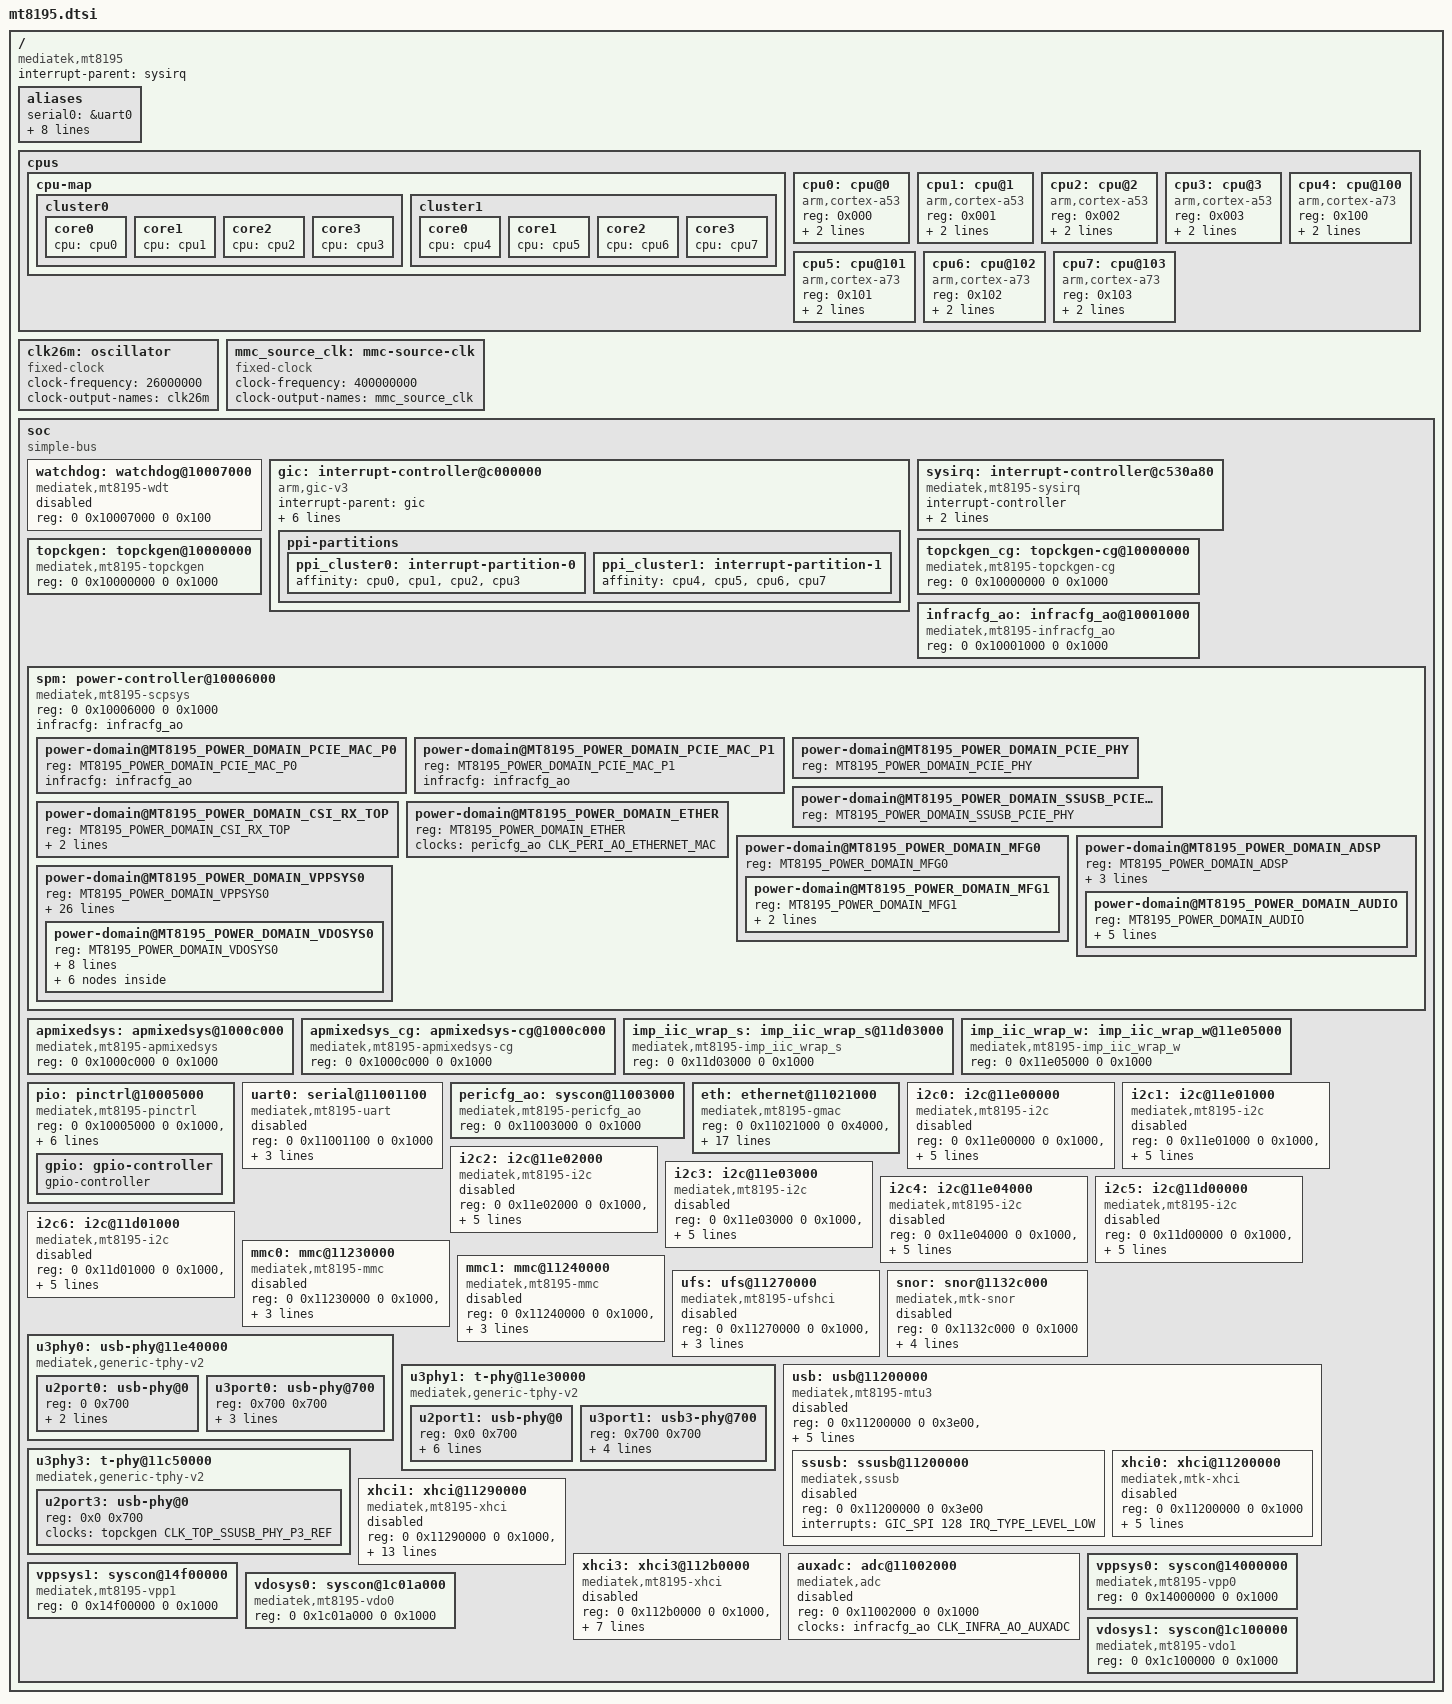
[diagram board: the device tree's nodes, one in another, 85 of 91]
// SPDX-License-Identifier: (GPL-2.0 OR MIT)
/*
 * Copyright (C) 2021 MediaTek Inc.
 * Copyright (C) 2021 BayLibre, SAS
 * Author: Ben Ho <ben.ho@mediatek.com>
 *         Erin Lo <erin.lo@mediatek.com>
 *         Fabien Parent <fparent@baylibre.com>
 */

#include <dt-bindings/gpio/gpio.h>
#include <dt-bindings/clock/mt8195-clk.h>
#include <dt-bindings/interrupt-controller/irq.h>
#include <dt-bindings/interrupt-controller/arm-gic.h>
#include <dt-bindings/pinctrl/mediatek,mt8195-pinfunc.h>
#include <dt-bindings/power/mt8195-power.h>
#include <dt-bindings/phy/phy.h>

/ {
	compatible = "mediatek,mt8195";
	interrupt-parent = <&sysirq>;
	#address-cells = <2>;
	#size-cells = <2>;

	aliases {
		serial0 = &uart0;
		ethernet0 = &eth;
		i2c0 = &i2c0;
		i2c1 = &i2c1;
		i2c2 = &i2c2;
		i2c3 = &i2c3;
		i2c4 = &i2c4;
		i2c5 = &i2c5;
		i2c6 = &i2c6;
	};

	cpus {
		#address-cells = <1>;
		#size-cells = <0>;

		cpu-map {
			cluster0 {
				core0 {
					cpu = <&cpu0>;
				};
				core1 {
					cpu = <&cpu1>;
				};
				core2 {
					cpu = <&cpu2>;
				};
				core3 {
					cpu = <&cpu3>;
				};
			};

			cluster1 {
				core0 {
					cpu = <&cpu4>;
				};
				core1 {
					cpu = <&cpu5>;
				};
				core2 {
					cpu = <&cpu6>;
				};
				core3 {
					cpu = <&cpu7>;
				};
			};
		};

		cpu0: cpu@0 {
			device_type = "cpu";
			compatible = "arm,cortex-a53";
			reg = <0x000>;
			enable-method = "psci";
			capacity-dmips-mhz = <741>;
		};

		cpu1: cpu@1 {
			device_type = "cpu";
			compatible = "arm,cortex-a53";
			reg = <0x001>;
			enable-method = "psci";
			capacity-dmips-mhz = <741>;
		};

		cpu2: cpu@2 {
			device_type = "cpu";
			compatible = "arm,cortex-a53";
			reg = <0x002>;
			enable-method = "psci";
			capacity-dmips-mhz = <741>;
		};

		cpu3: cpu@3 {
			device_type = "cpu";
			compatible = "arm,cortex-a53";
			reg = <0x003>;
			enable-method = "psci";
			capacity-dmips-mhz = <741>;
		};

		cpu4: cpu@100 {
			device_type = "cpu";
			compatible = "arm,cortex-a73";
			reg = <0x100>;
			enable-method = "psci";
			capacity-dmips-mhz = <1024>;
		};

		cpu5: cpu@101 {
			device_type = "cpu";
			compatible = "arm,cortex-a73";
			reg = <0x101>;
			enable-method = "psci";
			capacity-dmips-mhz = <1024>;
		};

		cpu6: cpu@102 {
			device_type = "cpu";
			compatible = "arm,cortex-a73";
			reg = <0x102>;
			enable-method = "psci";
			capacity-dmips-mhz = <1024>;
		};

		cpu7: cpu@103 {
			device_type = "cpu";
			compatible = "arm,cortex-a73";
			reg = <0x103>;
			enable-method = "psci";
			capacity-dmips-mhz = <1024>;
		};
	};

	clk26m: oscillator {
		compatible = "fixed-clock";
		#clock-cells = <0>;
		clock-frequency = <26000000>;
		clock-output-names = "clk26m";
	};

	mmc_source_clk: mmc-source-clk{
		compatible = "fixed-clock";
		#clock-cells = <0>;
		clock-frequency = <400000000>;
		clock-output-names = "mmc_source_clk";
	};

	soc {
		#address-cells = <2>;
		#size-cells = <2>;
		compatible = "simple-bus";
		ranges;

		watchdog: watchdog@10007000 {
			compatible = "mediatek,mt8195-wdt",
				      "mediatek,wdt";
			reg = <0 0x10007000 0 0x100>;
			status = "disabled";
		};

		gic: interrupt-controller@c000000 {
			compatible = "arm,gic-v3";
			#interrupt-cells = <4>;
			interrupt-parent = <&gic>;
			interrupt-controller;
			reg = <0 0x0c000000 0 0x40000>,  /* GICD */
			      <0 0x0c100000 0 0x200000>, /* GICR */
			      <0 0x0c400000 0 0x2000>,   /* GICC */
			      <0 0x0c410000 0 0x1000>,   /* GICH */
			      <0 0x0c420000 0 0x2000>;   /* GICV */

			interrupts = <GIC_PPI 9 IRQ_TYPE_LEVEL_HIGH 0>;
			ppi-partitions {
				ppi_cluster0: interrupt-partition-0 {
					affinity = <&cpu0 &cpu1 &cpu2 &cpu3>;
				};
				ppi_cluster1: interrupt-partition-1 {
					affinity = <&cpu4 &cpu5 &cpu6 &cpu7>;
				};
			};
		};

		sysirq: interrupt-controller@c530a80 {
			compatible = "mediatek,mt8195-sysirq",
				     "mediatek,mt6577-sysirq";
			interrupt-controller;
			#interrupt-cells = <3>;
			interrupt-parent = <&gic>;
			reg = <0 0x0c530a80 0 0x50>;
		};

		topckgen: topckgen@10000000 {
			compatible = "mediatek,mt8195-topckgen";
			reg = <0 0x10000000 0 0x1000>;
			#clock-cells = <1>;
		};

		topckgen_cg: topckgen-cg@10000000 {
			compatible = "mediatek,mt8195-topckgen-cg";
			reg = <0 0x10000000 0 0x1000>;
			#clock-cells = <1>;
		};

		infracfg_ao: infracfg_ao@10001000 {
			compatible = "mediatek,mt8195-infracfg_ao", "syscon";
			reg = <0 0x10001000 0 0x1000>;
			#clock-cells = <1>;
		};

		spm: power-controller@10006000 {
			compatible = "mediatek,mt8195-scpsys";
			reg = <0 0x10006000 0 0x1000>;
			#address-cells = <1>;
			#size-cells = <0>;
			#power-domain-cells = <1>;
			infracfg = <&infracfg_ao>;

			power-domain@MT8195_POWER_DOMAIN_PCIE_MAC_P0 {
				reg = <MT8195_POWER_DOMAIN_PCIE_MAC_P0>;
				infracfg = <&infracfg_ao>;
				#power-domain-cells = <0>;
			};

			power-domain@MT8195_POWER_DOMAIN_PCIE_MAC_P1 {
				reg = <MT8195_POWER_DOMAIN_PCIE_MAC_P1>;
				infracfg = <&infracfg_ao>;
				#power-domain-cells = <0>;
			};

			power-domain@MT8195_POWER_DOMAIN_PCIE_PHY {
				reg = <MT8195_POWER_DOMAIN_PCIE_PHY>;
				#power-domain-cells = <0>;
			};

			power-domain@MT8195_POWER_DOMAIN_SSUSB_PCIE_PHY {
				reg = <MT8195_POWER_DOMAIN_SSUSB_PCIE_PHY>;
				#power-domain-cells = <0>;
			};

			power-domain@MT8195_POWER_DOMAIN_CSI_RX_TOP {
				reg = <MT8195_POWER_DOMAIN_CSI_RX_TOP>;
				clocks = <&topckgen CLK_TOP_SENINF>,
					 <&topckgen CLK_TOP_SENINF2>;
				clock-names = "csi_rx_top", "csi_rx_top1";
				#power-domain-cells = <0>;
			};

			power-domain@MT8195_POWER_DOMAIN_ETHER {
				reg = <MT8195_POWER_DOMAIN_ETHER>;
				clocks = <&pericfg_ao CLK_PERI_AO_ETHERNET_MAC>;
				clock-names = "ether";
				#power-domain-cells = <0>;
			};

			power-domain@MT8195_POWER_DOMAIN_MFG0 {
				reg = <MT8195_POWER_DOMAIN_MFG0>;
				#address-cells = <1>;
				#size-cells = <0>;
				#power-domain-cells = <1>;

				power-domain@MT8195_POWER_DOMAIN_MFG1 {
					reg = <MT8195_POWER_DOMAIN_MFG1>;
					clocks = <&apmixedsys CLK_APMIXED_MFGPLL>;
					clock-names = "mfg";
					infracfg = <&infracfg_ao>;
					#address-cells = <1>;
					#size-cells = <0>;
					#power-domain-cells = <1>;
				};
			};

			power-domain@MT8195_POWER_DOMAIN_ADSP {
				reg = <MT8195_POWER_DOMAIN_ADSP>;
				clocks = <&topckgen CLK_TOP_ADSP>,
					 <&topckgen CLK_TOP_AUDIO_LOCAL_BUS>;
				clock-names = "adsp", "adsp1";
				#address-cells = <1>;
				#size-cells = <0>;
				infracfg = <&infracfg_ao>;
				#power-domain-cells = <1>;

				power-domain@MT8195_POWER_DOMAIN_AUDIO {
					reg = <MT8195_POWER_DOMAIN_AUDIO>;
					clocks = <&topckgen CLK_TOP_A1SYS_HP>,
						 <&topckgen CLK_TOP_AUD_INTBUS>,
						 <&topckgen CLK_TOP_AUDIO_LOCAL_BUS>,
						 <&infracfg_ao CLK_INFRA_AO_AUDIO_26M_B>;
					clock-names = "audio", "audio1", "audio-2",
							"audio-3";
					infracfg = <&infracfg_ao>;
					#power-domain-cells = <0>;
				};
			};

			power-domain@MT8195_POWER_DOMAIN_VPPSYS0 {
				reg = <MT8195_POWER_DOMAIN_VPPSYS0>;
				clocks = <&topckgen CLK_TOP_VPP>,
					 <&topckgen CLK_TOP_CAM>,
					 <&topckgen CLK_TOP_CCU>,
					 <&topckgen CLK_TOP_IMG>,
					 <&topckgen CLK_TOP_VENC>,
					 <&topckgen CLK_TOP_VDEC>,
					 <&topckgen CLK_TOP_WPE_VPP>,
					 <&topckgen CLK_TOP_CFG_VPP0>,
					 <&vppsys0 CLK_VPP0_SMI_COMMON>,
					 <&vppsys0 CLK_VPP0_GALS_VDO0_LARB0>,
					 <&vppsys0 CLK_VPP0_GALS_VDO0_LARB1>,
					 <&vppsys0 CLK_VPP0_GALS_VENCSYS>,
					 <&vppsys0 CLK_VPP0_GALS_VENCSYS_CORE1>,
					 <&vppsys0 CLK_VPP0_GALS_INFRA>,
					 <&vppsys0 CLK_VPP0_GALS_CAMSYS>,
					 <&vppsys0 CLK_VPP0_GALS_VPP1_LARB5>,
					 <&vppsys0 CLK_VPP0_GALS_VPP1_LARB6>,
					 <&vppsys0 CLK_VPP0_SMI_REORDER>,
					 <&vppsys0 CLK_VPP0_SMI_IOMMU>,
					 <&vppsys0 CLK_VPP0_GALS_IMGSYS_CAMSYS>,
					 <&vppsys0 CLK_VPP0_GALS_EMI0_EMI1>,
					 <&vppsys0 CLK_VPP0_SMI_SUB_COMMON_REORDER>,
					 <&vppsys0 CLK_VPP0_SMI_RSI>,
					 <&vppsys0 CLK_VPP0_SMI_COMMON_LARB4>,
					 <&vppsys0 CLK_VPP0_GALS_VDEC_VDEC_CORE1>,
					 <&vppsys0 CLK_VPP0_GALS_VPP1_WPE>,
					 <&vppsys0 CLK_VPP0_GALS_VDO0_VDO1_VENCSYS_CORE1>;
				clock-names = "vppsys", "vppsys1", "vppsys2", "vppsys3",
					      "vppsys4", "vppsys5", "vppsys6", "vppsys7",
					      "vppsys0-0", "vppsys0-1", "vppsys0-2", "vppsys0-3",
					      "vppsys0-4", "vppsys0-5", "vppsys0-6", "vppsys0-7",
					      "vppsys0-8", "vppsys0-9", "vppsys0-10", "vppsys0-11",
					      "vppsys0-12", "vppsys0-13", "vppsys0-14",
					      "vppsys0-15", "vppsys0-16", "vppsys0-17",
					      "vppsys0-18";
				infracfg = <&infracfg_ao>;
				#address-cells = <1>;
				#size-cells = <0>;
				#power-domain-cells = <1>;

				power-domain@MT8195_POWER_DOMAIN_VDOSYS0 {
					reg = <MT8195_POWER_DOMAIN_VDOSYS0>;
					clocks = <&topckgen CLK_TOP_CFG_VDO0>,
						 <&vdosys0 CLK_VDO0_SMI_GALS>,
						 <&vdosys0 CLK_VDO0_SMI_COMMON>,
						 <&vdosys0 CLK_VDO0_SMI_EMI>,
						 <&vdosys0 CLK_VDO0_SMI_IOMMU>,
						 <&vdosys0 CLK_VDO0_SMI_LARB>,
						 <&vdosys0 CLK_VDO0_SMI_RSI>;
					clock-names = "vdosys0", "vdosys0-0", "vdosys0-1",
						      "vdosys0-2", "vdosys0-3",
						      "vdosys0-4", "vdosys0-5";
					infracfg = <&infracfg_ao>;
					#address-cells = <1>;
					#size-cells = <0>;
					#power-domain-cells = <1>;

					power-domain@MT8195_POWER_DOMAIN_VPPSYS1 {
						reg = <MT8195_POWER_DOMAIN_VPPSYS1>;
						clocks = <&topckgen CLK_TOP_CFG_VPP1>,
							 <&vppsys1 CLK_VPP1_VPPSYS1_GALS>,
							 <&vppsys1 CLK_VPP1_VPPSYS1_LARB>;
						clock-names = "vppsys1", "vppsys1-0",
							      "vppsys1-1";
						infracfg = <&infracfg_ao>;
						#power-domain-cells = <0>;
					};

					power-domain@MT8195_POWER_DOMAIN_VDOSYS1 {
						reg = <MT8195_POWER_DOMAIN_VDOSYS1>;
						clocks = <&topckgen CLK_TOP_CFG_VDO1>,
							 <&vdosys1 CLK_VDO1_SMI_LARB2>,
							 <&vdosys1 CLK_VDO1_SMI_LARB3>,
							 <&vdosys1 CLK_VDO1_GALS>;
						clock-names = "vdosys1", "vdosys1-0",
							      "vdosys1-1", "vdosys1-2";
						infracfg = <&infracfg_ao>;
						#address-cells = <1>;
						#size-cells = <0>;
						#power-domain-cells = <1>;

						power-domain@MT8195_POWER_DOMAIN_DP_TX {
							reg = <MT8195_POWER_DOMAIN_DP_TX>;
							infracfg = <&infracfg_ao>;
							#power-domain-cells = <0>;
						};

						power-domain@MT8195_POWER_DOMAIN_EPD_TX {
							reg = <MT8195_POWER_DOMAIN_EPD_TX>;
							infracfg = <&infracfg_ao>;
							#power-domain-cells = <0>;
						};

						power-domain@MT8195_POWER_DOMAIN_HDMI_TX {
							reg = <MT8195_POWER_DOMAIN_HDMI_TX>;
							clocks = <&topckgen CLK_TOP_HDMI_APB>;
							clock-names = "hdmi_tx";
							#power-domain-cells = <0>;
						};

						power-domain@MT8195_POWER_DOMAIN_HDMI_RX {
							reg = <MT8195_POWER_DOMAIN_HDMI_RX>;
							clocks = <&topckgen CLK_TOP_HDMI_APB>;
							clock-names = "hdmi_rx";
							#power-domain-cells = <0>;
						};
					};
				};
			};
		};

		apmixedsys: apmixedsys@1000c000 {
			compatible = "mediatek,mt8195-apmixedsys";
			reg = <0 0x1000c000 0 0x1000>;
			#clock-cells = <1>;
		};

		apmixedsys_cg: apmixedsys-cg@1000c000 {
			compatible = "mediatek,mt8195-apmixedsys-cg";
			reg = <0 0x1000c000 0 0x1000>;
			#clock-cells = <1>;
		};

		imp_iic_wrap_s: imp_iic_wrap_s@11d03000 {
			compatible = "mediatek,mt8195-imp_iic_wrap_s";
			reg = <0 0x11d03000 0 0x1000>;
			#clock-cells = <1>;
		};

		imp_iic_wrap_w: imp_iic_wrap_w@11e05000 {
			compatible = "mediatek,mt8195-imp_iic_wrap_w";
			reg = <0 0x11e05000 0 0x1000>;
			#clock-cells = <1>;
		};

		pio: pinctrl@10005000 {
			compatible = "mediatek,mt8195-pinctrl";
			reg = <0 0x10005000 0 0x1000>,
			      <0 0x11d10000 0 0x1000>,
			      <0 0x11d30000 0 0x1000>,
			      <0 0x11d40000 0 0x1000>,
			      <0 0x11e20000 0 0x1000>,
			      <0 0x11eb0000 0 0x1000>,
			      <0 0x11f40000 0 0x1000>,
			      <0 0x1000b000 0 0x1000>;
			reg-names = "iocfg0", "iocfg_bm", "iocfg_bl",
				    "iocfg_br", "iocfg_lm", "iocfg_rb",
				    "iocfg_tl", "eint";
			gpio: gpio-controller {
				gpio-controller;
				#gpio-cells = <2>;
			};
		};

		uart0: serial@11001100 {
			compatible = "mediatek,mt8195-uart",
				     "mediatek,hsuart";
			reg = <0 0x11001100 0 0x1000>;
			interrupts = <GIC_SPI 91 IRQ_TYPE_LEVEL_LOW>;
			clock-frequency = <26000000>;
			clocks = <&clk26m>, <&clk26m>;
			clock-names = "baud", "bus";
			status = "disabled";
		};

		pericfg_ao: syscon@11003000 {
			compatible = "mediatek,mt8195-pericfg_ao", "syscon";
			reg = <0 0x11003000 0 0x1000>;
			#clock-cells = <1>;
		};

		eth: ethernet@11021000 {
			compatible = "mediatek,mt8195-gmac", "snps,dwmac-5.10a";
			reg = <0 0x11021000 0 0x4000>,
			/* TODO: remove it when power driver is ready*/
				  <0 0x10006000 0 0x1000>;
			interrupts = <GIC_SPI 716 IRQ_TYPE_LEVEL_HIGH 0>;
			interrupt-names = "macirq";
			clock-names = "axi",
				      "apb",
				      "mac_cg",
				      "mac_main",
				      "ptp_ref",
				      "rmii_internal";
			clocks = <&pericfg_ao CLK_PERI_AO_ETHERNET>,
				 <&pericfg_ao CLK_PERI_AO_ETHERNET_BUS>,
				 <&pericfg_ao CLK_PERI_AO_ETHERNET_MAC>,
				 <&topckgen CLK_TOP_SNPS_ETH_250M>,
				 <&topckgen CLK_TOP_SNPS_ETH_62P4M_PTP>,
				 <&topckgen CLK_TOP_SNPS_ETH_50M_RMII>;
			assigned-clocks = <&topckgen CLK_TOP_SNPS_ETH_250M>,
					  <&topckgen CLK_TOP_SNPS_ETH_62P4M_PTP>,
					  <&topckgen CLK_TOP_SNPS_ETH_50M_RMII>;
			assigned-clock-parents = <&topckgen CLK_TOP_ETHPLL_D2>,
						 <&topckgen CLK_TOP_ETHPLL_D8>,
						 <&topckgen CLK_TOP_ETHPLL_D10>;
			/*power-domains = <&spm MT8195_POWER_DOMAIN_ETHER>;*/
			mediatek,pericfg = <&infracfg_ao>;
			status = "okay";
		};

		i2c0: i2c@11e00000 {
			compatible = "mediatek,mt8195-i2c";
			reg = <0 0x11e00000 0 0x1000>,
			      <0 0x10220080 0 0x80>;
			clock-div = <1>;
			clocks = <&imp_iic_wrap_w CLK_IMP_IIC_WRAP_W_I2C0>,
				 <&infracfg_ao CLK_INFRA_AO_APDMA_B>;
			clock-names = "main", "dma";
			#address-cells = <1>;
			#size-cells = <0>;
			status = "disabled";
		};

		i2c1: i2c@11e01000 {
			compatible = "mediatek,mt8195-i2c";
			reg = <0 0x11e01000 0 0x1000>,
			      <0 0x10220200 0 0x80>;
			clock-div = <1>;
			clocks = <&imp_iic_wrap_w CLK_IMP_IIC_WRAP_W_I2C1>,
				 <&infracfg_ao CLK_INFRA_AO_APDMA_B>;
			clock-names = "main", "dma";
			#address-cells = <1>;
			#size-cells = <0>;
			status = "disabled";
		};

		i2c2: i2c@11e02000 {
			compatible = "mediatek,mt8195-i2c";
			reg = <0 0x11e02000 0 0x1000>,
			      <0 0x10220380 0 0x80>;
			clock-div = <1>;
			clocks = <&imp_iic_wrap_w CLK_IMP_IIC_WRAP_W_I2C2>,
				 <&infracfg_ao CLK_INFRA_AO_APDMA_B>;
			clock-names = "main", "dma";
			#address-cells = <1>;
			#size-cells = <0>;
			status = "disabled";
		};

		i2c3: i2c@11e03000 {
			compatible = "mediatek,mt8195-i2c";
			reg = <0 0x11e03000 0 0x1000>,
			      <0 0x10220480 0 0x80>;
			clock-div = <1>;
			clocks = <&imp_iic_wrap_w CLK_IMP_IIC_WRAP_W_I2C3>,
				 <&infracfg_ao CLK_INFRA_AO_APDMA_B>;
			clock-names = "main", "dma";
			#address-cells = <1>;
			#size-cells = <0>;
			status = "disabled";
		};

		i2c4: i2c@11e04000 {
			compatible = "mediatek,mt8195-i2c";
			reg = <0 0x11e04000 0 0x1000>,
			      <0 0x10220500 0 0x80>;
			clock-div = <1>;
			clocks = <&imp_iic_wrap_w CLK_IMP_IIC_WRAP_W_I2C4>,
				 <&infracfg_ao CLK_INFRA_AO_APDMA_B>;
			clock-names = "main", "dma";
			#address-cells = <1>;
			#size-cells = <0>;
			status = "disabled";
		};

		i2c5: i2c@11d00000 {
			compatible = "mediatek,mt8195-i2c";
			reg = <0 0x11d00000 0 0x1000>,
			      <0 0x10220580 0 0x80>;
			clock-div = <1>;
			clocks = <&imp_iic_wrap_s CLK_IMP_IIC_WRAP_S_I2C5>,
				 <&infracfg_ao CLK_INFRA_AO_APDMA_B>;
			clock-names = "main", "dma";
			#address-cells = <1>;
			#size-cells = <0>;
			status = "disabled";
		};

		i2c6: i2c@11d01000 {
			compatible = "mediatek,mt8195-i2c";
			reg = <0 0x11d01000 0 0x1000>,
				<0 0x10220600 0 0x80>;
			clock-div = <1>;
			clocks = <&imp_iic_wrap_s CLK_IMP_IIC_WRAP_S_I2C6>,
				<&infracfg_ao CLK_INFRA_AO_APDMA_B>;
			clock-names = "main", "dma";
			#address-cells = <1>;
			#size-cells = <0>;
			status = "disabled";
		};

		mmc0: mmc@11230000 {
			compatible = "mediatek,mt8195-mmc",
				     "mediatek,mt8183-mmc";
			reg = <0 0x11230000 0 0x1000>,
			      <0 0x11f50000 0 0x1000>;
			interrupts = <GIC_SPI 77 IRQ_TYPE_LEVEL_LOW>;
			clocks = <&mmc_source_clk>,
				 <&clk26m>,
				 <&clk26m>;
			clock-names = "source", "hclk", "source_cg";
			status = "disabled";
		};

		mmc1: mmc@11240000 {
			compatible = "mediatek,mt8195-mmc",
				     "mediatek,mt8183-mmc";
			reg = <0 0x11240000 0 0x1000>,
			      <0 0x11c70000 0 0x1000>;
			interrupts = <GIC_SPI 135 IRQ_TYPE_LEVEL_LOW>;
			clocks = <&mmc_source_clk>,
				 <&clk26m>,
				 <&clk26m>;
			clock-names = "source", "hclk", "source_cg";
			status = "disabled";
		};

		ufs: ufs@11270000 {
			compatible = "mediatek,mt8195-ufshci",
				     "mediatek,mt8183-ufshci";
			reg = <0 0x11270000 0 0x1000>,
			      <0 0x11f50000 0 0x1000>;
			interrupts = <GIC_SPI 77 IRQ_TYPE_LEVEL_LOW>;
			clocks = <&mmc_source_clk>,
				 <&clk26m>,
				 <&clk26m>;
			clock-names = "source", "hclk", "source_cg";
			status = "disabled";
		};

		snor: snor@1132c000 {
			compatible = "mediatek,mtk-snor";
			reg = <0 0x1132c000 0 0x1000>;
			interrupts = <GIC_SPI 825 IRQ_TYPE_LEVEL_HIGH 0>;
			clocks = <&topckgen CLK_TOP_SPINOR>,
				 <&pericfg_ao CLK_PERI_AO_FLASHIF_FLASH>,
				 <&pericfg_ao CLK_PERI_AO_FLASHIF_BUS>;
			clock-names = "spi", "sf", "axi";
			#address-cells = <1>;
			#size-cells = <0>;
			status = "disabled";
		};

		u3phy0: usb-phy@11e40000 {
			compatible = "mediatek,generic-tphy-v2";
			#address-cells = <1>;
			#size-cells = <1>;
			ranges = <0 0 0x11e40000 0xe00>;
			status = "okay";

			u2port0: usb-phy@0 {
				reg = <0 0x700>;
				clocks = <&topckgen CLK_TOP_SSUSB_PHY_REF>,
					 <&apmixedsys CLK_APMIXED_USB1PLL>;
				clock-names = "ref", "da_ref";
				#phy-cells = <1>;
				status = "okay";
			};

			u3port0: usb-phy@700 {
				reg = <0x700 0x700>;
				clocks = <&apmixedsys_cg CLK_APMIXED_PLL_SSUSB26M>,
					 <&topckgen CLK_TOP_SSUSB_PHY_REF>;
				clock-names = "ref", "da_ref";
				#phy-cells = <1>;
				status = "okay";
			};
		};

		u3phy1: t-phy@11e30000 {
			compatible = "mediatek,generic-tphy-v2";
			#address-cells = <1>;
			#size-cells = <1>;
			ranges = <0 0 0x11e30000 0xe00>;
			status = "okay";

			u2port1: usb-phy@0 {
				reg = <0x0 0x700>;
				clocks = <&topckgen CLK_TOP_SSUSB_PHY_P1_REF>,
					 <&apmixedsys CLK_APMIXED_USB1PLL>;
				clock-names = "ref", "da_ref";
				#phy-cells = <1>;
				mediatek,eye-vrt = <4>;
				mediatek,eye-term = <4>;
				mediatek,discth = <4>;
				mediatek,pre-emphasis = <0>;
				status = "okay";
			};

			u3port1: usb3-phy@700 {
				reg = <0x700 0x700>;
				clocks = <&apmixedsys_cg CLK_APMIXED_PLL_SSUSB26M>,
					<&topckgen CLK_TOP_SSUSB_PHY_P1_REF>;
				clock-names = "ref", "da_ref";
				#phy-cells = <1>;
				mediatek,force-mode;
				status = "okay";
			};
		};

		usb: usb@11200000 {
			compatible ="mediatek,mt8195-mtu3", "mediatek,mtu3";
			reg = <0 0x11200000 0 0x3e00>,
			      <0 0x11203e00 0 0x0100>;
			reg-names = "mac", "ippc";
			phys = <&u2port0 PHY_TYPE_USB2>;
			clocks = <&infracfg_ao CLK_INFRA_AO_SSUSB>,
				 <&topckgen CLK_TOP_SSUSB_REF>,
				 <&infracfg_ao CLK_INFRA_AO_SSUSB_XHCI>;
			clock-names = "sys_ck", "ref_ck", "mcu_ck";
			#address-cells = <2>;
			#size-cells = <2>;
			ranges;
			status = "disabled";

			ssusb: ssusb@11200000 {
				compatible = "mediatek,ssusb";
				reg = <0 0x11200000 0 0x3e00>;
				reg-names = "mac";
				interrupts = <GIC_SPI 128 IRQ_TYPE_LEVEL_LOW>;
				status = "disabled";
			};

			xhci0: xhci@11200000 {
				compatible = "mediatek,mtk-xhci";
				reg = <0 0x11200000 0 0x1000>;
				reg-names = "mac";
				interrupts = <GIC_SPI 129 IRQ_TYPE_LEVEL_LOW>;
				clocks = <&infracfg_ao CLK_INFRA_AO_SSUSB>,
					 <&infracfg_ao CLK_INFRA_AO_SSUSB_XHCI>,
					 <&topckgen CLK_TOP_SSUSB_REF>,
					 <&apmixedsys CLK_APMIXED_USB1PLL>;
				clock-names = "sys_ck", "xhci_ck", "ref_ck", "mcu_ck";
				status = "disabled";
			};
		};

		u3phy3: t-phy@11c50000 {
			compatible = "mediatek,generic-tphy-v2";
			#address-cells = <1>;
			#size-cells = <1>;
			ranges = <0 0 0x11c50000 0x700>;
			status = "okay";

			u2port3: usb-phy@0 {
				reg = <0x0 0x700>;
				clocks = <&topckgen CLK_TOP_SSUSB_PHY_P3_REF>;
				clock-names = "ref";
				#phy-cells = <1>;
			};
		};

		xhci1: xhci@11290000 {
			compatible = "mediatek,mt8195-xhci",
				     "mediatek,mtk-xhci";
			reg = <0 0x11290000 0 0x1000>,
			      <0 0x11293e00 0 0x0100>;
			reg-names = "mac", "ippc";
			interrupts = <GIC_SPI 530 IRQ_TYPE_LEVEL_HIGH 0>;
			phys = <&u2port1 PHY_TYPE_USB2>,
			       <&u3port1 PHY_TYPE_USB3>;
			assigned-clocks = <&topckgen CLK_TOP_USB_TOP_1P>,
					  <&topckgen CLK_TOP_SSUSB_XHCI_1P>;
			assigned-clock-parents = <&topckgen CLK_TOP_UNIVPLL_D5_D4>,
						 <&topckgen CLK_TOP_UNIVPLL_D5_D4>;
			clocks = <&pericfg_ao CLK_PERI_AO_SSUSB_1P_BUS>,
				 <&pericfg_ao CLK_PERI_AO_SSUSB_1P_XHCI>,
				 <&topckgen CLK_TOP_SSUSB_P1_REF>,
				 <&apmixedsys CLK_APMIXED_USB1PLL>;
			clock-names = "sys_ck", "xhci_ck", "ref_ck", "mcu_ck";
			status = "disable";
		};

		xhci3: xhci3@112b0000 {
			compatible = "mediatek,mt8195-xhci",
				     "mediatek,mtk-xhci";
			reg = <0 0x112b0000 0 0x1000>,
			      <0 0x112b3e00 0 0x0100>;
			reg-names = "mac", "ippc";
			interrupts = <GIC_SPI 536 IRQ_TYPE_LEVEL_HIGH>;
			phys = <&u2port3 PHY_TYPE_USB2>;
			clocks = <&pericfg_ao CLK_PERI_AO_SSUSB_3P_BUS>,
				 <&pericfg_ao CLK_PERI_AO_SSUSB_3P_XHCI>,
				 <&topckgen CLK_TOP_SSUSB_P3_REF>;
			clock-names = "sys_ck", "xhci_ck", "ref_ck";
			usb2-lpm-disable;
			status = "disabled";
		};

		auxadc: adc@11002000 {
			compatible = "mediatek,adc";
			reg = <0 0x11002000 0 0x1000>;
			clocks = <&infracfg_ao CLK_INFRA_AO_AUXADC>;
			clock-names = "main";
			#io-channel-cells = <1>;
			status = "disabled";
		};

		vppsys0: syscon@14000000 {
			compatible = "mediatek,mt8195-vpp0", "syscon";
			reg = <0 0x14000000 0 0x1000>;
			#clock-cells = <1>;
		};

		vppsys1: syscon@14f00000 {
			compatible = "mediatek,mt8195-vpp1", "syscon";
			reg = <0 0x14f00000 0 0x1000>;
			#clock-cells = <1>;
		};

		vdosys0: syscon@1c01a000 {
			compatible = "mediatek,mt8195-vdo0", "syscon";
			reg = <0 0x1c01a000 0 0x1000>;
			#clock-cells = <1>;
		};

		vdosys1: syscon@1c100000 {
			compatible = "mediatek,mt8195-vdo1", "syscon";
			reg = <0 0x1c100000 0 0x1000>;
			#clock-cells = <1>;
		};
	};
};
